VERSION ""

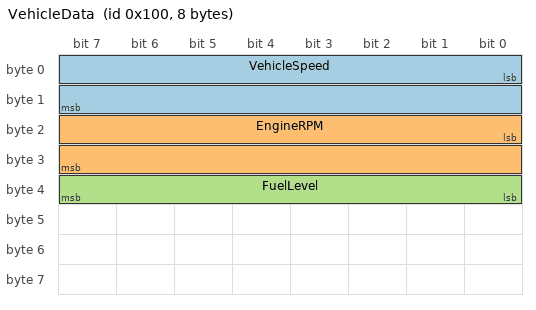
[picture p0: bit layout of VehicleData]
BO_ 256 VehicleData: 8 Vector__XXX
 SG_ VehicleSpeed : 0|16@1+ (0.01,0) [0|250] "km/h" Vector__XXX
 SG_ EngineRPM : 16|16@1+ (1,0) [0|8000] "rpm" Vector__XXX
 SG_ FuelLevel : 32|8@1+ (1,0) [0|100] "%" Vector__XXX
